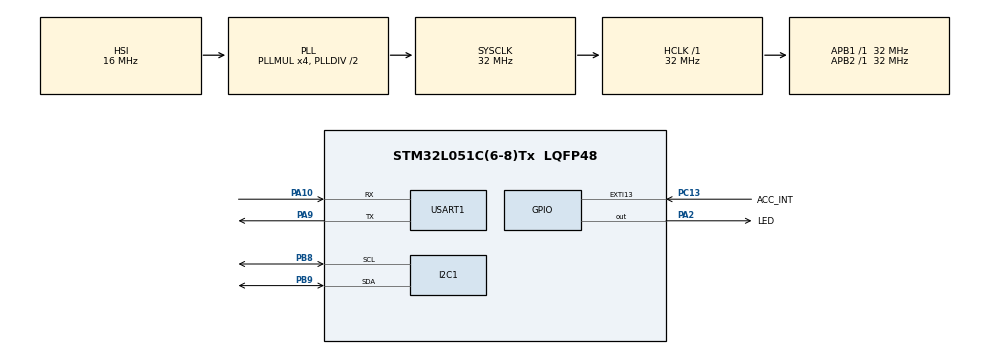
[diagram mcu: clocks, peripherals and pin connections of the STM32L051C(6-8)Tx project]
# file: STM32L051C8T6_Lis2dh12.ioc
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I2C1.Timing=0x00707CBB
Mcu.Family=STM32L0
Mcu.Name=STM32L051C(6-8)Tx
Mcu.Package=LQFP48
PA10.Mode=Asynchronous
PA10.Signal=USART1_RX
PA13.Mode=Serial_Wire
PA13.Signal=SYS_SWDIO
PA14.Mode=Serial_Wire
PA14.Signal=SYS_SWCLK
PA2.GPIO_Label=LED
PA2.Signal=GPIO_Output
PA9.Mode=Asynchronous
PA9.Signal=USART1_TX
PB8.Mode=I2C
PB8.Signal=I2C1_SCL
PB9.Mode=I2C
PB9.Signal=I2C1_SDA
PC13.GPIO_Label=ACC_INT
PC13.Signal=GPXTI13
ProjectManager.HeapSize=0x200
ProjectManager.StackSize=0x400
ProjectManager.TargetToolchain=STM32CubeIDE
RCC.AHBFreq_Value=32000000
RCC.APB1Freq_Value=32000000
RCC.APB1TimFreq_Value=32000000
RCC.APB2Freq_Value=32000000
RCC.APB2TimFreq_Value=32000000
RCC.HCLKFreq_Value=32000000
RCC.HSE_VALUE=8000000
RCC.HSI16_VALUE=16000000
RCC.HSI_VALUE=16000000
RCC.LSE_VALUE=32768
RCC.MSI_VALUE=2097000
RCC.PLLMUL=RCC_PLLMUL_4
RCC.SYSCLKFreq_VALUE=32000000
RCC.SYSCLKSource=RCC_SYSCLKSOURCE_PLLCLK
RCC.VCOOutputFreq_Value=64000000
USART1.VirtualMode-Asynchronous=VM_ASYNC
board=custom

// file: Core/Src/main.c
/* USER CODE BEGIN Header */
/**
  ******************************************************************************
  * @file           : main.c
  * @brief          : Main program body
  ******************************************************************************
  * @attention
  *
  * <h2><center>&copy; Copyright (c) 2020 STMicroelectronics.
  * All rights reserved.</center></h2>
  *
  * This software component is licensed by ST under BSD 3-Clause license,
  * the "License"; You may not use this file except in compliance with the
  * License. You may obtain a copy of the License at:
  *                        opensource.org/licenses/BSD-3-Clause
  *
  ******************************************************************************
  */
/* USER CODE END Header */

#include "main.h"
#include "i2c.h"
#include "usart.h"
#include "gpio.h"

/* USER CODE BEGIN Includes */
#include "stdio.h"

#include "lis2dh12.h"
/* USER CODE END Includes */

void SystemClock_Config(void);

int main(void)
{

  /* MCU Configuration--------------------------------------------------------*/

  /* Reset of all peripherals, Initializes the Flash interface and the Systick. */
  HAL_Init();

  /* Configure the system clock */
  SystemClock_Config();

  /* Initialize all configured peripherals */
  MX_GPIO_Init();
  MX_I2C1_Init();
  MX_USART1_UART_Init();
  /* USER CODE BEGIN 2 */
  filter_calculate(&acc_data, &acc_sample);
  old_angle_calculate(&acc_sample);
  /* USER CODE END 2 */

  /* Infinite loop */
  /* USER CODE BEGIN WHILE */
  while (1)
  {
	 HAL_Delay(1000);
	 filter_calculate(&acc_data, &acc_sample);
	 new_angle_calculate(&acc_sample);
    /* USER CODE END WHILE */

  }
}

void SystemClock_Config(void)
{
  RCC_OscInitTypeDef RCC_OscInitStruct = {0};
  RCC_ClkInitTypeDef RCC_ClkInitStruct = {0};
  RCC_PeriphCLKInitTypeDef PeriphClkInit = {0};

  /** Configure the main internal regulator output voltage
  */
  __HAL_PWR_VOLTAGESCALING_CONFIG(PWR_REGULATOR_VOLTAGE_SCALE1);
  /** Initializes the CPU, AHB and APB busses clocks
  */
  RCC_OscInitStruct.OscillatorType = RCC_OSCILLATORTYPE_HSI;
  RCC_OscInitStruct.HSIState = RCC_HSI_ON;
  RCC_OscInitStruct.HSICalibrationValue = RCC_HSICALIBRATION_DEFAULT;
  RCC_OscInitStruct.PLL.PLLState = RCC_PLL_ON;
  RCC_OscInitStruct.PLL.PLLSource = RCC_PLLSOURCE_HSI;
  RCC_OscInitStruct.PLL.PLLMUL = RCC_PLLMUL_4;
  RCC_OscInitStruct.PLL.PLLDIV = RCC_PLLDIV_2;
  if (HAL_RCC_OscConfig(&RCC_OscInitStruct) != HAL_OK)
  {
    Error_Handler();
  }
  /** Initializes the CPU, AHB and APB busses clocks
  */
  RCC_ClkInitStruct.ClockType = RCC_CLOCKTYPE_HCLK|RCC_CLOCKTYPE_SYSCLK
                              |RCC_CLOCKTYPE_PCLK1|RCC_CLOCKTYPE_PCLK2;
  RCC_ClkInitStruct.SYSCLKSource = RCC_SYSCLKSOURCE_PLLCLK;
  RCC_ClkInitStruct.AHBCLKDivider = RCC_SYSCLK_DIV1;
  RCC_ClkInitStruct.APB1CLKDivider = RCC_HCLK_DIV1;
  RCC_ClkInitStruct.APB2CLKDivider = RCC_HCLK_DIV1;

  if (HAL_RCC_ClockConfig(&RCC_ClkInitStruct, FLASH_LATENCY_1) != HAL_OK)
  {
    Error_Handler();
  }
  PeriphClkInit.PeriphClockSelection = RCC_PERIPHCLK_USART1|RCC_PERIPHCLK_I2C1;
  PeriphClkInit.Usart1ClockSelection = RCC_USART1CLKSOURCE_PCLK2;
  PeriphClkInit.I2c1ClockSelection = RCC_I2C1CLKSOURCE_PCLK1;
  if (HAL_RCCEx_PeriphCLKConfig(&PeriphClkInit) != HAL_OK)
  {
    Error_Handler();
  }
}

void Error_Handler(void)
{
}

/************************ (C) COPYRIGHT STMicroelectronics *****END OF FILE****/
